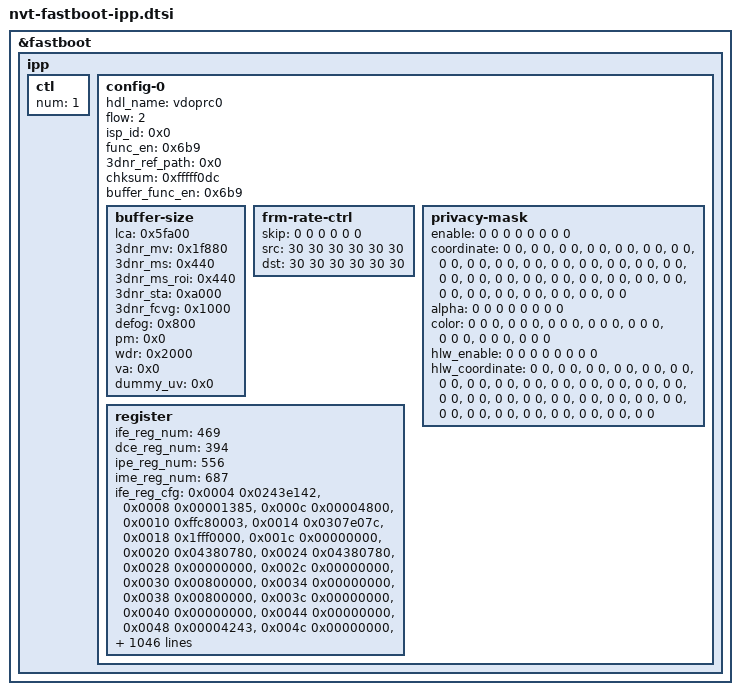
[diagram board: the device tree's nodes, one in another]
&fastboot {
	ipp {
		ctl {
			num = <1>;
		};
		config-0 {
			hdl_name = "vdoprc0";
			flow = <2>;
			isp_id = <0x0>;
			func_en = <0x6b9>;
			3dnr_ref_path = <0x0>;
			chksum = <0xfffff0dc>;
			buffer_func_en = <0x6b9>;
			buffer-size {
				lca = <0x5fa00>;
				3dnr_mv = <0x1f880>;
				3dnr_ms = <0x440>;
				3dnr_ms_roi = <0x440>;
				3dnr_sta = <0xa000>;
				3dnr_fcvg = <0x1000>;
				defog = <0x800>;
				pm = <0x0>;
				wdr = <0x2000>;
				va = <0x0>;
				dummy_uv = <0x0>;
			};
			frm-rate-ctrl {
				skip = <0 0 0 0 0 0>;
				src = <30 30 30 30 30 30>;
				dst = <30 30 30 30 30 30>;
			};
			privacy-mask {
				enable = <0 0 0 0 0 0 0 0>;
				coordinate =
					<0 0>, <0 0>, <0 0>, <0 0>,
					<0 0>, <0 0>, <0 0>, <0 0>,
					<0 0>, <0 0>, <0 0>, <0 0>,
					<0 0>, <0 0>, <0 0>, <0 0>,
					<0 0>, <0 0>, <0 0>, <0 0>,
					<0 0>, <0 0>, <0 0>, <0 0>,
					<0 0>, <0 0>, <0 0>, <0 0>,
					<0 0>, <0 0>, <0 0>, <0 0>;
				alpha = <0 0 0 0 0 0 0 0>;
				color =
					<0 0 0>,
					<0 0 0>,
					<0 0 0>,
					<0 0 0>,
					<0 0 0>,
					<0 0 0>,
					<0 0 0>,
					<0 0 0>;
				hlw_enable = <0 0 0 0 0 0 0 0>;
				hlw_coordinate =
					<0 0>, <0 0>, <0 0>, <0 0>,
					<0 0>, <0 0>, <0 0>, <0 0>,
					<0 0>, <0 0>, <0 0>, <0 0>,
					<0 0>, <0 0>, <0 0>, <0 0>,
					<0 0>, <0 0>, <0 0>, <0 0>,
					<0 0>, <0 0>, <0 0>, <0 0>,
					<0 0>, <0 0>, <0 0>, <0 0>,
					<0 0>, <0 0>, <0 0>, <0 0>;
			};
			register {
			  ife_reg_num = <469>;
			  dce_reg_num = <394>;
			  ipe_reg_num = <556>;
			  ime_reg_num = <687>;

			  ife_reg_cfg = 
			    <0x0004 0x0243e142>,
			    <0x0008 0x00001385>,
			    <0x000c 0x00004800>,
			    <0x0010 0xffc80003>,
			    <0x0014 0x0307e07c>,
			    <0x0018 0x1fff0000>,
			    <0x001c 0x00000000>,
			    <0x0020 0x04380780>,
			    <0x0024 0x04380780>,
			    <0x0028 0x00000000>,
			    <0x002c 0x00000000>,
			    <0x0030 0x00800000>,
			    <0x0034 0x00000000>,
			    <0x0038 0x00800000>,
			    <0x003c 0x00000000>,
			    <0x0040 0x00000000>,
			    <0x0044 0x00000000>,
			    <0x0048 0x00004243>,
			    <0x004c 0x00000000>,
			    <0x0050 0x00000000>,
			    <0x0054 0x00800000>,
			    <0x0058 0x00000000>,
			    <0x005c 0x00000000>,
			    <0x0060 0x00000000>,
			    <0x0064 0x00000000>,
			    <0x0068 0x000007a2>,
			    <0x006c 0x0001b987>,
			    <0x0070 0x000fff08>,
			    <0x0074 0x01120178>,
			    <0x0078 0x02670112>,
			    <0x007c 0x00000112>,
			    <0x0080 0x00800080>,
			    <0x0084 0x00800080>,
			    <0x0088 0x00000080>,
			    <0x008c 0x00800080>,
			    <0x0090 0x00800080>,
			    <0x0094 0x00000080>,
			    <0x0098 0x00000000>,
			    <0x009c 0x00000000>,
			    <0x00a0 0x00000000>,
			    <0x00a4 0x00000000>,
			    <0x00a8 0x00000000>,
			    <0x00ac 0x00000000>,
			    <0x00b0 0x01000100>,
			    <0x00b4 0x01000100>,
			    <0x00b8 0x00000100>,
			    <0x00bc 0x00000000>,
			    <0x00c0 0x00000000>,
			    <0x00c4 0x00000000>,
			    <0x00c8 0x00000000>,
			    <0x00cc 0x00000000>,
			    <0x00d0 0x00000000>,
			    <0x00d4 0x00000000>,
			    <0x00d8 0x00000000>,
			    <0x00dc 0x00000000>,
			    <0x00e0 0x00000000>,
			    <0x00e4 0x00000000>,
			    <0x00e8 0x00000000>,
			    <0x00ec 0x00000000>,
			    <0x00f0 0x00000000>,
			    <0x00f4 0x00000000>,
			    <0x00f8 0x00000000>,
			    <0x00fc 0x00000000>,
			    <0x0100 0x00080040>,
			    <0x0104 0x00000000>,
			    <0x0108 0x0911171f>,
			    <0x010c 0x00000307>,
			    <0x0110 0x00020000>,
			    <0x0114 0x00040003>,
			    <0x0118 0x00060005>,
			    <0x011c 0x00000000>,
			    <0x0120 0x00020000>,
			    <0x0124 0x00040003>,
			    <0x0128 0x00060005>,
			    <0x012c 0x00000000>,
			    <0x0130 0x00020000>,
			    <0x0134 0x00040003>,
			    <0x0138 0x00060005>,
			    <0x013c 0x00000000>,
			    <0x0140 0x00020000>,
			    <0x0144 0x00040003>,
			    <0x0148 0x00060005>,
			    <0x014c 0x00000000>,
			    <0x0150 0x00060000>,
			    <0x0154 0x000b0008>,
			    <0x0158 0x0013000e>,
			    <0x015c 0x00000000>,
			    <0x0160 0x00060000>,
			    <0x0164 0x000b0008>,
			    <0x0168 0x0013000e>,
			    <0x016c 0x00000000>,
			    <0x0170 0x00060000>,
			    <0x0174 0x000b0008>,
			    <0x0178 0x0013000e>,
			    <0x017c 0x00000000>,
			    <0x0180 0x00060000>,
			    <0x0184 0x000b0008>,
			    <0x0188 0x0013000e>,
			    <0x018c 0x00000000>,
			    <0x0190 0x002c62c6>,
			    <0x0194 0x0040c40c>,
			    <0x0198 0x006af6af>,
			    <0x019c 0x0093d93d>,
			    <0x01a0 0x00f41f41>,
			    <0x01a4 0x00010000>,
			    <0x01a8 0x00010033>,
			    <0x01ac 0x86543210>,
			    <0x01b0 0x86543210>,
			    <0x01b4 0x00f00001>,
			    <0x01b8 0x008000a0>,
			    <0x01bc 0x000010ff>,
			    <0x01c0 0x00030000>,
			    <0x01c4 0x00040003>,
			    <0x01c8 0x00060005>,
			    <0x01cc 0x00070006>,
			    <0x01d0 0x00080007>,
			    <0x01d4 0x00080008>,
			    <0x01d8 0x00090009>,
			    <0x01dc 0x000a0009>,
			    <0x01e0 0x0000000a>,
			    <0x01e4 0x00030000>,
			    <0x01e8 0x00040003>,
			    <0x01ec 0x00060005>,
			    <0x01f0 0x00070006>,
			    <0x01f4 0x00080007>,
			    <0x01f8 0x00080008>,
			    <0x01fc 0x00090009>,
			    <0x0200 0x000a0009>,
			    <0x0204 0x0000000a>,
			    <0x0208 0x00030000>,
			    <0x020c 0x00040003>,
			    <0x0210 0x00060005>,
			    <0x0214 0x00070006>,
			    <0x0218 0x00080007>,
			    <0x021c 0x00080008>,
			    <0x0220 0x00090009>,
			    <0x0224 0x000a0009>,
			    <0x0228 0x0000000a>,
			    <0x022c 0x00030000>,
			    <0x0230 0x00040003>,
			    <0x0234 0x00060005>,
			    <0x0238 0x00070006>,
			    <0x023c 0x00080007>,
			    <0x0240 0x00080008>,
			    <0x0244 0x00090009>,
			    <0x0248 0x000a0009>,
			    <0x024c 0x0000000a>,
			    <0x0250 0x00030000>,
			    <0x0254 0x00040003>,
			    <0x0258 0x00060005>,
			    <0x025c 0x00070006>,
			    <0x0260 0x00080007>,
			    <0x0264 0x00080008>,
			    <0x0268 0x00090009>,
			    <0x026c 0x000a0009>,
			    <0x0270 0x0000000a>,
			    <0x0274 0x00030000>,
			    <0x0278 0x00040003>,
			    <0x027c 0x00060005>,
			    <0x0280 0x00070006>,
			    <0x0284 0x00080007>,
			    <0x0288 0x00080008>,
			    <0x028c 0x00090009>,
			    <0x0290 0x000a0009>,
			    <0x0294 0x0000000a>,
			    <0x0298 0x00030000>,
			    <0x029c 0x00040003>,
			    <0x02a0 0x00060005>,
			    <0x02a4 0x00070006>,
			    <0x02a8 0x00080007>,
			    <0x02ac 0x00080008>,
			    <0x02b0 0x00090009>,
			    <0x02b4 0x000a0009>,
			    <0x02b8 0x0000000a>,
			    <0x02bc 0x00030000>,
			    <0x02c0 0x00040003>,
			    <0x02c4 0x00060005>,
			    <0x02c8 0x00070006>,
			    <0x02cc 0x00080007>,
			    <0x02d0 0x00080008>,
			    <0x02d4 0x00090009>,
			    <0x02d8 0x000a0009>,
			    <0x02dc 0x0000000a>,
			    <0x02e0 0x021c03c0>,
			    <0x02e4 0x021c03c0>,
			    <0x02e8 0x021c03c0>,
			    <0x02ec 0x021c03c0>,
			    <0x02f0 0x003b73b8>,
			    <0x02f4 0xfffc0001>,
			    <0x02f8 0x00000000>,
			    <0x02fc 0x00000000>,
			    <0x0300 0x00000000>,
			    <0x0304 0x00000000>,
			    <0x0308 0x00000000>,
			    <0x030c 0x00000000>,
			    <0x0310 0x00000000>,
			    <0x0314 0x00000000>,
			    <0x0318 0x00000000>,
			    <0x031c 0x00000000>,
			    <0x0320 0x00000000>,
			    <0x0324 0x00000000>,
			    <0x0328 0x00000000>,
			    <0x032c 0x00000000>,
			    <0x0330 0x00000000>,
			    <0x0334 0x00000000>,
			    <0x0338 0x00000000>,
			    <0x033c 0x00000000>,
			    <0x0340 0x00000000>,
			    <0x0344 0x00000000>,
			    <0x0348 0x00000000>,
			    <0x034c 0x00000000>,
			    <0x0350 0x00000000>,
			    <0x0354 0x00000000>,
			    <0x0358 0x00000000>,
			    <0x035c 0x00000000>,
			    <0x0360 0x00000000>,
			    <0x0364 0x00000000>,
			    <0x0368 0x00000000>,
			    <0x036c 0x00000000>,
			    <0x0370 0x00000000>,
			    <0x0374 0x00000000>,
			    <0x0378 0x00000000>,
			    <0x037c 0x00000000>,
			    <0x0380 0x00000000>,
			    <0x0384 0x00000000>,
			    <0x0388 0x09060301>,
			    <0x038c 0x15120f0d>,
			    <0x0390 0x211e1b18>,
			    <0x0394 0x2d2a2724>,
			    <0x0398 0x00000030>,
			    <0x039c 0x1b181000>,
			    <0x03a0 0x1f1e1c1b>,
			    <0x03a4 0x1c1d1e1f>,
			    <0x03a8 0x0c1a1b1c>,
			    <0x03ac 0x00000004>,
			    <0x03b0 0x00000000>,
			    <0x03b4 0x00000000>,
			    <0x03b8 0x00000000>,
			    <0x03bc 0x00000000>,
			    <0x03c0 0x1f1f1f1f>,
			    <0x03c4 0x1e1e1f1f>,
			    <0x03c8 0x14181c1d>,
			    <0x03cc 0x080a0c10>,
			    <0x03d0 0x06060606>,
			    <0x03d4 0x05050505>,
			    <0x03d8 0x04040404>,
			    <0x03dc 0x20010203>,
			    <0x03e0 0x00000000>,
			    <0x03e4 0x00000000>,
			    <0x03e8 0x00000000>,
			    <0x03ec 0x00000000>,
			    <0x03f0 0x00000000>,
			    <0x03f4 0x00000000>,
			    <0x03f8 0x00000000>,
			    <0x03fc 0x00000000>,
			    <0x0400 0x80000000>,
			    <0x0404 0x00000000>,
			    <0x0408 0x00000000>,
			    <0x040c 0x01000000>,
			    <0x0410 0x00000000>,
			    <0x0414 0x00000000>,
			    <0x0418 0x00000000>,
			    <0x041c 0x01000000>,
			    <0x0420 0x00000000>,
			    <0x0424 0x00000000>,
			    <0x0428 0x00000000>,
			    <0x042c 0x00000000>,
			    <0x0430 0x00000000>,
			    <0x0434 0x00000000>,
			    <0x0438 0x00000000>,
			    <0x043c 0x00000000>,
			    <0x0440 0x00000000>,
			    <0x0444 0x00000000>,
			    <0x0448 0x00000000>,
			    <0x044c 0x00000000>,
			    <0x0450 0x00000000>,
			    <0x0454 0x00000000>,
			    <0x0458 0x00000000>,
			    <0x045c 0x00000000>,
			    <0x0460 0x00000000>,
			    <0x0464 0x00000000>,
			    <0x0468 0x00000000>,
			    <0x046c 0x00000000>,
			    <0x0470 0x00000000>,
			    <0x0474 0x00000000>,
			    <0x0478 0x00000000>,
			    <0x047c 0x00000000>,
			    <0x0480 0x00000000>,
			    <0x0484 0x00000000>,
			    <0x0488 0x00000000>,
			    <0x048c 0x00000000>,
			    <0x0490 0x00000000>,
			    <0x0494 0x00000000>,
			    <0x0498 0x00000000>,
			    <0x049c 0x00000000>,
			    <0x04a0 0x00000000>,
			    <0x04a4 0x00000000>,
			    <0x04a8 0x00000000>,
			    <0x04ac 0x00000000>,
			    <0x04b0 0x00000000>,
			    <0x04b4 0x00000000>,
			    <0x04b8 0x00000000>,
			    <0x04bc 0x00000000>,
			    <0x04c0 0x00000000>,
			    <0x04c4 0x00000000>,
			    <0x04c8 0x00000000>,
			    <0x04cc 0x00000000>,
			    <0x04d0 0x00000000>,
			    <0x04d4 0x00000000>,
			    <0x04d8 0x00000000>,
			    <0x04dc 0x00000000>,
			    <0x04e0 0x00000000>,
			    <0x04e4 0x00000000>,
			    <0x04e8 0x00000000>,
			    <0x04ec 0x00000000>,
			    <0x04f0 0x00000000>,
			    <0x04f4 0x00000000>,
			    <0x04f8 0x00000000>,
			    <0x04fc 0x00000000>,
			    <0x0500 0x00000000>,
			    <0x0504 0x00000000>,
			    <0x0508 0x00000000>,
			    <0x050c 0x00000000>,
			    <0x0510 0x00000000>,
			    <0x0514 0x00000000>,
			    <0x0518 0x00000000>,
			    <0x051c 0x00000000>,
			    <0x0520 0x00000000>,
			    <0x0524 0x00000000>,
			    <0x0528 0x00000000>,
			    <0x052c 0x00000000>,
			    <0x0530 0x00000000>,
			    <0x0534 0x00000000>,
			    <0x0538 0x00000000>,
			    <0x053c 0x00000000>,
			    <0x0540 0x00000000>,
			    <0x0544 0x00000000>,
			    <0x0548 0x00000000>,
			    <0x054c 0x00000000>,
			    <0x0550 0x00100210>,
			    <0x0554 0x0e009c00>,
			    <0x0558 0x810060c0>,
			    <0x055c 0x0e009c00>,
			    <0x0560 0x810060c0>,
			    <0x0564 0x00000000>,
			    <0x0568 0x00000000>,
			    <0x056c 0x00000000>,
			    <0x0570 0x00000100>,
			    <0x0574 0x18a41040>,
			    <0x0578 0x10a63a0e>,
			    <0x057c 0x00000886>,
			    <0x0580 0x18a41040>,
			    <0x0584 0x10a63a0e>,
			    <0x0588 0x00000886>,
			    <0x058c 0x00000000>,
			    <0x0590 0xff100fff>,
			    <0x0594 0xff100fff>,
			    <0x0598 0x00000000>,
			    <0x059c 0x00000000>,
			    <0x05a0 0x00000000>,
			    <0x05a4 0x00000000>,
			    <0x05a8 0x00000000>,
			    <0x05ac 0x00000000>,
			    <0x05b0 0x00002222>,
			    <0x05b4 0x00000000>,
			    <0x05b8 0x00000000>,
			    <0x05bc 0x00000000>,
			    <0x05c0 0x00000000>,
			    <0x05c4 0x00000000>,
			    <0x05c8 0x00000000>,
			    <0x05cc 0x00000000>,
			    <0x05d0 0x00000000>,
			    <0x05d4 0x00000000>,
			    <0x05d8 0x00000000>,
			    <0x05dc 0x00000000>,
			    <0x05e0 0x00000000>,
			    <0x05e4 0x00000000>,
			    <0x05e8 0x00000000>,
			    <0x05ec 0x00000000>,
			    <0x05f0 0x00000000>,
			    <0x05f4 0x00000000>,
			    <0x05f8 0x00000000>,
			    <0x05fc 0x00000000>,
			    <0x0600 0x00000000>,
			    <0x0604 0x00000000>,
			    <0x0608 0x00000000>,
			    <0x060c 0x00000000>,
			    <0x0610 0x00000000>,
			    <0x0614 0x00000000>,
			    <0x0618 0x00000000>,
			    <0x061c 0x00000000>,
			    <0x0620 0x00000000>,
			    <0x0624 0x00000000>,
			    <0x0628 0x00000000>,
			    <0x062c 0x00000000>,
			    <0x0630 0x00000000>,
			    <0x0634 0x00000000>,
			    <0x0638 0x00000000>,
			    <0x063c 0x00000000>,
			    <0x0640 0x00000000>,
			    <0x0644 0x00000000>,
			    <0x0648 0x00000000>,
			    <0x064c 0x00000000>,
			    <0x0650 0x00000000>,
			    <0x0654 0x00000000>,
			    <0x0658 0x00000000>,
			    <0x065c 0x00000000>,
			    <0x0660 0x00000000>,
			    <0x0664 0x00000000>,
			    <0x0668 0x00000000>,
			    <0x066c 0x00000000>,
			    <0x0670 0x00000000>,
			    <0x0674 0x00000000>,
			    <0x0678 0x00000000>,
			    <0x067c 0x00000000>,
			    <0x0680 0x00000000>,
			    <0x0684 0x00000000>,
			    <0x0688 0x00000000>,
			    <0x068c 0x00000000>,
			    <0x0690 0x00000000>,
			    <0x0694 0x00000000>,
			    <0x0698 0x00000000>,
			    <0x069c 0x00000000>,
			    <0x06a0 0x00000000>,
			    <0x06a4 0x00000000>,
			    <0x06a8 0x00000000>,
			    <0x06ac 0x00000000>,
			    <0x06b0 0x00000000>,
			    <0x06b4 0x00000000>,
			    <0x06b8 0x00000000>,
			    <0x06bc 0x00000000>,
			    <0x06c0 0x00000000>,
			    <0x06c4 0x00000000>,
			    <0x06c8 0x00000000>,
			    <0x06cc 0x00000000>,
			    <0x06d0 0x00000000>,
			    <0x06d4 0x00000000>,
			    <0x06d8 0x00000000>,
			    <0x06dc 0x00000000>,
			    <0x06e0 0x00000000>,
			    <0x06e4 0x00000000>,
			    <0x06e8 0x00000000>,
			    <0x06ec 0x00000000>,
			    <0x06f0 0x00000000>,
			    <0x06f4 0x00000000>,
			    <0x06f8 0x00000000>,
			    <0x06fc 0x00000000>,
			    <0x0700 0x00000000>,
			    <0x0704 0x00000000>,
			    <0x0708 0x00000000>,
			    <0x070c 0x00000000>,
			    <0x0710 0x0002aaaa>,
			    <0x0714 0x00000000>,
			    <0x0718 0x00000000>,
			    <0x071c 0x00000000>,
			    <0x0720 0x00000000>,
			    <0x0724 0x00000000>,
			    <0x0728 0x00000000>,
			    <0x072c 0x00000000>,
			    <0x0730 0x00000000>,
			    <0x0734 0x00000000>,
			    <0x0738 0x00000000>,
			    <0x073c 0x00000000>,
			    <0x0740 0x00000000>,
			    <0x0744 0x00000000>,
			    <0x0748 0x00000000>,
			    <0x074c 0x00000000>,
			    <0x0750 0x00000000>,
			    <0x0754 0x00000000>;

			  dce_reg_cfg = 
			    <0x0004 0x0000467a>,
			    <0x0008 0x0000101b>,
			    <0x000c 0x00000000>,
			    <0x0010 0x04380780>,
			    <0x0014 0x00000000>,
			    <0x0018 0x00000010>,
			    <0x001c 0x00400000>,
			    <0x0020 0x00400000>,
			    <0x0024 0x00000780>,
			    <0x0028 0x00400000>,
			    <0x002c 0x00000780>,
			    <0x0030 0x00400000>,
			    <0x0034 0x00000780>,
			    <0x0038 0x00400000>,
			    <0x003c 0x00000780>,
			    <0x0040 0x00000011>,
			    <0x0044 0x1e0781e0>,
			    <0x0048 0x1e0781e0>,
			    <0x004c 0x1e0781e0>,
			    <0x0050 0x1e0781e0>,
			    <0x0054 0x1e0781e0>,
			    <0x0058 0x000001e0>,
			    <0x005c 0x7f000000>,
			    <0x0060 0x00003003>,
			    <0x0064 0x077f0000>,
			    <0x0068 0x077f0000>,
			    <0x006c 0x0000001e>,
			    <0x0070 0x00000000>,
			    <0x0074 0x00000000>,
			    <0x0078 0x00000000>,
			    <0x007c 0x00000000>,
			    <0x0080 0x00000000>,
			    <0x0084 0x00000000>,
			    <0x0088 0x00000000>,
			    <0x008c 0x00000780>,
			    <0x0090 0x00000000>,
			    <0x0094 0x00000000>,
			    <0x0098 0x00000000>,
			    <0x009c 0x00000000>,
			    <0x00a0 0x00000000>,
			    <0x00a4 0x00400000>,
			    <0x00a8 0x2c0003c0>,
			    <0x00ac 0x000a0028>,
			    <0x00b0 0x80000000>,
			    <0x00b4 0x00000000>,
			    <0x00b8 0xf8888888>,
			    <0x00bc 0x485f7880>,
			    <0x00c0 0x2428303a>,
			    <0x00c4 0x20202020>,
			    <0x00c8 0x20202020>,
			    <0x00cc 0x00a00020>,
			    <0x00d0 0x00014008>,
			    <0x00d4 0x122347ff>,
			    <0x00d8 0x00000111>,
			    <0x00dc 0x00000000>,
			    <0x00e0 0x40081007>,
			    <0x00e4 0x00408003>,
			    <0x00e8 0x00cc00cc>,
			    <0x00ec 0xa80080e6>,
			    <0x00f0 0x00800080>,
			    <0x00f4 0x00010080>,
			    <0x00f8 0x00000100>,
			    <0x00fc 0xffffe0c0>,
			    <0x0100 0x00000000>,
			    <0x0104 0x00000000>,
			    <0x0108 0x00000000>,
			    <0x010c 0x00000000>,
			    <0x0110 0x00000000>,
			    <0x0114 0x00000000>,
			    <0x0118 0x00000000>,
			    <0x011c 0x00000000>,
			    <0x0120 0x0000023f>,
			    <0x0124 0x02c53f40>,
			    <0x0128 0x00000100>,
			    <0x012c 0x02c51f40>,
			    <0x0130 0x00000100>,
			    <0x0134 0x04080422>,
			    <0x0138 0x0f79cc3b>,
			    <0x013c 0x0fde1c3b>,
			    <0x0140 0x00000000>,
			    <0x0144 0x00000000>,
			    <0x0148 0x00000000>,
			    <0x014c 0x00000000>,
			    <0x0150 0x00000000>,
			    <0x0154 0x20000000>,
			    <0x0158 0x00000054>,
			    <0x015c 0x1565193c>,
			    <0x0160 0x160c160c>,
			    <0x0164 0x55050003>,
			    <0x0168 0x00000000>,
			    <0x016c 0x00000000>,
			    <0x0170 0x00000000>,
			    <0x0174 0x00000000>,
			    <0x0178 0x00000000>,
			    <0x017c 0x00000000>,
			    <0x0180 0x00000000>,
			    <0x0184 0x00000000>,
			    <0x0188 0x00000000>,
			    <0x018c 0x00000000>,
			    <0x0190 0x00000000>,
			    <0x0194 0x00000000>,
			    <0x0198 0x00000000>,
			    <0x019c 0x00000000>,
			    <0x01a0 0x00000000>,
			    <0x01a4 0x00000000>,
			    <0x01a8 0x00000000>,
			    <0x01ac 0x00000000>,
			    <0x01b0 0x00000000>,
			    <0x01b4 0x00000000>,
			    <0x01b8 0x00000000>,
			    <0x01bc 0x00000000>,
			    <0x01c0 0x00000000>,
			    <0x01c4 0x00000000>,
			    <0x01c8 0x00000000>,
			    <0x01cc 0x00000000>,
			    <0x01d0 0x00000000>,
			    <0x01d4 0x00000000>,
			    <0x01d8 0x00000000>,
			    <0x01dc 0x00000000>,
			    <0x01e0 0x00000000>,
			    <0x01e4 0x00000000>,
			    <0x01e8 0x00000000>,
			    <0x01ec 0x00000000>,
			    <0x01f0 0x00000000>,
			    <0x01f4 0x00000000>,
			    <0x01f8 0x00000000>,
			    <0x01fc 0x00000000>,
			    <0x0200 0x00000000>,
			    <0x0204 0x00000000>,
			    <0x0208 0x00000000>,
			    <0x020c 0x00000000>,
			    <0x0210 0x00000000>,
			    <0x0214 0x18100800>,
			    <0x0218 0x2624201c>,
			    <0x021c 0x2b2a2928>,
			    <0x0220 0x2f2e2d2c>,
			    <0x0224 0x33323130>,
			    <0x0228 0x37363534>,
			    <0x022c 0x3b3a3938>,
			    <0x0230 0x3f3e3d3c>,
			    <0x0234 0x00005abf>,
			    <0x0238 0x00000000>,
			    <0x023c 0x0ff70fff>,
			    <0x0240 0x0fa10fd8>,
			    <0x0244 0x0ef10f54>,
			    <0x0248 0x0df70e7b>,
			    <0x024c 0x0cd10d68>,
			    <0x0250 0x0b9d0c37>,
			    <0x0254 0x0a700b04>,
			    <0x0258 0x095909e1>,
			    <0x025c 0x085f08d8>,
			    <0x0260 0x078407ee>,
			    <0x0264 0x06c70722>,
			    <0x0268 0x06240673>,
			    <0x026c 0x055c05dc>,
			    <0x0270 0x049004ee>,
			    <0x0274 0x03f9043f>,
			    <0x0278 0x038803bd>,
			    <0x027c 0x0332035b>,
			    <0x0280 0x02f0030f>,
			    <0x0284 0x02a602d4>,
			    <0x0288 0x02620280>,
			    <0x028c 0x02230249>,
			    <0x0290 0x01f30208>,
			    <0x0294 0x01d801e4>,
			    <0x0298 0x01c801cf>,
			    <0x029c 0x01bd01c2>,
			    <0x02a0 0x01b501b9>,
			    <0x02a4 0x01b001b2>,
			    <0x02a8 0x01ac01ae>,
			    <0x02ac 0x01a901aa>,
			    <0x02b0 0x01a601a7>,
			    <0x02b4 0x01a401a5>,
			    <0x02b8 0x01a301a4>,
			    <0x02bc 0x000001a2>,
			    <0x02c0 0x00008040>,
			    <0x02c4 0xffff0000>,
			    <0x02c8 0x00000000>,
			    <0x02cc 0x00000000>,
			    <0x02d0 0x00000000>,
			    <0x02d4 0x00000000>,
			    <0x02d8 0x020a0000>,
			    <0x02dc 0x2bba0c3b>,
			    <0x02e0 0xb8c3749e>,
			    <0x02e4 0xffffffff>,
			    <0x02e8 0xffffffff>,
			    <0x02ec 0xffffffff>,
			    <0x02f0 0xe1c1ffff>,
			    <0x02f4 0xcf72e582>,
			    <0x02f8 0x9468acbd>,
			    <0x02fc 0x74608664>,
			    <0x0300 0x68946fc0>,
			    <0x0304 0x4b605fce>,
			    <0x0308 0x2f573b99>,
			    <0x030c 0x29122d1b>,
			    <0x0310 0x2363257f>,
			    <0x0314 0x21ab2390>,
			    <0x0318 0x1d8d1f29>,
			    <0x031c 0x20091db5>,
			    <0x0320 0x24f425d0>,
			    <0x0324 0x228c23ca>,
			    <0x0328 0x2816233c>,
			    <0x032c 0x33bc2f0b>,
			    <0x0330 0x30b130b5>,
			    <0x0334 0x30b1300c>,
			    <0x0338 0x2f5b2fc0>,
			    <0x033c 0x2bc22e56>,
			    <0x0340 0x28e72a17>,
			    <0x0344 0x2c2a2605>,
			    <0x0348 0x2a9e2f6e>,
			    <0x034c 0x264525ac>,
			    <0x0350 0x275a26fd>,
			    <0x0354 0x28af28b7>,
			    <0x0358 0x25a526eb>,
			    <0x035c 0x20f32345>,
			    <0x0360 0x1b891de8>,
			    <0x0364 0x1b961af1>,
			    <0x0368 0x1cf11bb3>,
			    <0x036c 0x26c71f83>,
			    <0x0370 0x34f83350>,
			    <0x0374 0x2b432dc9>,
			    <0x0378 0x29cd2881>,
			    <0x037c 0x2aed2c94>,
			    <0x0380 0x2c902c79>,
			    <0x0384 0x22a2290d>,
			    <0x0388 0x17d31a7a>,
			    <0x038c 0x130a16ec>,
			    <0x0390 0x0e631047>,
			    <0x0394 0x0d580db3>,
			    <0x0398 0x0d180d60>,
			    <0x039c 0x0b690c2f>,
			    <0x03a0 0x0c650be4>,
			    <0x03a4 0x0bb70b4c>,
			    <0x03a8 0x0ac80b07>,
			    <0x03ac 0x0acb0ab9>,
			    <0x03b0 0x0a920add>,
			    <0x03b4 0x0a000aad>,
			    <0x03b8 0x0b860a9f>,
			    <0x03bc 0x0c190bc9>,
			    <0x03c0 0x0d500cfb>,
			    <0x03c4 0x0f1b0e2f>,
			    <0x03c8 0x135410cc>,
			    <0x03cc 0x1afe1743>,
			    <0x03d0 0xffff2093>,
			    <0x03d4 0x00000000>,
			    <0x03d8 0x00000000>,
			    <0x03dc 0x00000000>,
			    <0x03e0 0x00000000>,
			    <0x03e4 0x00000000>,
			    <0x03e8 0x00000000>,
			    <0x03ec 0x00000000>,
			    <0x03f0 0x00000000>,
			    <0x03f4 0x00000000>,
			    <0x03f8 0x00000000>,
			    <0x03fc 0x00000000>,
			    <0x0400 0x00000000>,
			    <0x0404 0x021c03c0>,
			    <0x0408 0x00ffffff>,
			    <0x040c 0x032916ca>,
			    <0x0410 0x00000400>,
			    <0x0414 0x3fffffff>,
			    <0x0418 0x10001000>,
			    <0x041c 0x00001000>,
			    <0x0420 0x00000000>,
			    <0x0424 0x00000000>,
			    <0x0428 0x00000000>,
			    <0x042c 0x00000000>,
			    <0x0430 0x00000000>,
			    <0x0434 0x00000000>,
			    <0x0438 0x00000000>,
			    <0x043c 0x00000000>,
			    <0x0440 0xffffffff>,
			    <0x0444 0xffffffff>,
			    <0x0448 0xffffffff>,
			    <0x044c 0xffffffff>,
			    <0x0450 0xffffffff>,
			    <0x0454 0xffffffff>,
			    <0x0458 0xffffffff>,
			    <0x045c 0xffffffff>,
			    <0x0460 0xffffffff>,
			    <0x0464 0xffffffff>,
			    <0x0468 0xffffffff>,
			    <0x046c 0xffffffff>,
			    <0x0470 0xffffffff>,
			    <0x0474 0xffffffff>,
			    <0x0478 0xffffffff>,
			    <0x047c 0xffffffff>,
			    <0x0480 0xffffffff>,
			    <0x0484 0xffffffff>,
			    <0x0488 0xffffffff>,
			    <0x048c 0xffffffff>,
			    <0x0490 0xffffffff>,
			    <0x0494 0xffffffff>,
			    <0x0498 0xffffffff>,
			    <0x049c 0xffffffff>,
			    <0x04a0 0xffffffff>,
			    <0x04a4 0xffffffff>,
			    <0x04a8 0xffffffff>,
			    <0x04ac 0xffffffff>,
			    <0x04b0 0xffffffff>,
			    <0x04b4 0xffffffff>,
			    <0x04b8 0xffffffff>,
			    <0x04bc 0xffffffff>,
			    <0x04c0 0x0000ffff>,
			    <0x04c4 0x00000000>,
			    <0x04c8 0x00000000>,
			    <0x04cc 0x00000000>,
			    <0x04d0 0x00000000>,
			    <0x04d4 0x00000000>,
			    <0x04d8 0x00000000>,
			    <0x04dc 0x00000000>,
			    <0x04e0 0x00000000>,
			    <0x04e4 0x00000000>,
			    <0x04e8 0x00000000>,
			    <0x04ec 0x00000000>,
			    <0x04f0 0x00000000>,
			    <0x04f4 0x00000000>,
			    <0x04f8 0x00000000>,
			    <0x04fc 0x00000000>,
			    <0x0500 0x00000000>,
			    <0x0504 0x00000000>,
			    <0x0508 0x00000000>,
			    <0x050c 0x00000000>,
			    <0x0510 0x00000000>,
			    <0x0514 0x00000000>,
			    <0x0518 0x00000000>,
			    <0x051c 0x00000000>,
			    <0x0520 0x00000000>,
			    <0x0524 0x00000000>,
			    <0x0528 0x00000000>,
			    <0x052c 0x00000000>,
			    <0x0530 0x00000000>,
			    <0x0534 0x00000000>,
			    <0x0538 0x00000000>,
			    <0x053c 0x00000000>,
			    <0x0540 0x00000000>,
			    <0x0544 0x00000000>,
			    <0x0548 0x00000000>,
			    <0x054c 0x00000000>,
			    <0x0550 0x00000000>,
			    <0x0554 0x00000000>,
			    <0x0558 0x00000000>,
			    <0x055c 0x00000000>,
			    <0x0560 0x00000000>,
			    <0x0564 0x00000000>,
			    <0x0568 0x00000000>,
			    <0x056c 0x00000000>,
			    <0x0570 0x00000000>,
			    <0x0574 0x00000000>,
			    <0x0578 0x00000000>,
			    <0x057c 0x00000000>,
			    <0x0580 0x00000000>,
			    <0x0584 0x00000000>,
			    <0x0588 0x00000000>,
			    <0x058c 0x00000000>,
			    <0x0590 0x00000000>,
			    <0x0594 0x00000000>,
			    <0x0598 0x00000000>,
			    <0x059c 0x00000000>,
			    <0x05a0 0x00000000>,
			    <0x05a4 0x00000000>,
			    <0x05a8 0x00000000>,
			    <0x05ac 0x00000000>,
			    <0x05b0 0x00000000>,
			    <0x05b4 0x00000000>,
			    <0x05b8 0x00000000>,
			    <0x05bc 0x00000000>,
			    <0x05c0 0x00000000>,
			    <0x05c4 0x00000000>,
			    <0x05c8 0x00000000>,
			    <0x05cc 0x00000000>,
			    <0x05d0 0x00000000>,
			    <0x05d4 0x00000000>,
			    <0x05d8 0x00000000>,
			    <0x05dc 0x00000000>,
			    <0x05e0 0x00000000>,
			    <0x05e4 0x00000000>,
			    <0x05e8 0x00000000>,
			    <0x05ec 0x00000000>,
			    <0x05f0 0x00400000>,
			    <0x05f4 0x00000000>,
			    <0x05f8 0x00000000>,
			    <0x05fc 0x00000000>,
			    <0x0600 0x00000000>,
			    <0x0604 0x00000000>,
			    <0x0608 0x00000000>,
			    <0x060c 0x00000000>,
			    <0x0610 0x20200930>,
			    <0x0614 0x00000000>,
			    <0x0618 0x00000000>,
			    <0x061c 0x00000000>,
			    <0x0620 0x00000000>,
			    <0x0624 0x00000000>,
			    <0x0628 0x80000000>;

			  ipe_reg_cfg = 
			    <0x0004 0x00000006>,
			    <0x0008 0x01f17eda>,
			    <0x000c 0x00000010>,
			    <0x0010 0x00000000>,
			    <0x0014 0x001e0000>,
			    <0x0018 0x00000438>,
			    <0x001c 0x00000000>,
			    <0x0020 0x00000000>,
			    <0x0024 0x00000000>,
			    <0x0028 0x00000000>,
			    <0x002c 0x02b6dcfc>,
			    <0x0030 0x00000000>,
			    <0x0034 0x00000000>,
			    <0x0038 0x00800000>,
			    <0x003c 0x00800000>,
			    <0x0040 0x00000000>,
			    <0x0044 0x00000000>,
			    <0x0048 0x10000000>,
			    <0x004c 0x00000000>,
			    <0x0050 0x0000100a>,
			    <0x0054 0x00000064>,
			    <0x0058 0xff040001>,
			    <0x005c 0x00000000>,
			    <0x0060 0x00000000>,
			    <0x0064 0x00000000>,
			    <0x0068 0x00000000>,
			    <0x006c 0x00000000>,
			    <0x0070 0x017c05a3>,
			    <0x0074 0x3e2ec02a>,
			    <0x0078 0x00a013dd>,
			    <0x007c 0x0010100a>,
			    <0x0080 0x00181818>,
			    <0x0084 0x00000333>,
			    <0x0088 0x00010004>,
			    <0x008c 0x00008868>,
			    <0x0090 0x88681000>,
			    <0x0094 0x00082028>,
			    <0x0098 0xffc8201f>,
			    <0x009c 0x00a500b6>,
			    <0x00a0 0x00800801>,
			    <0x00a4 0xffff3180>,
			    <0x00a8 0x00010000>,
			    <0x00ac 0x01000100>,
			    <0x00b0 0x00600060>,
			    <0x00b4 0x05080000>,
			    <0x00b8 0x40352d20>,
			    <0x00bc 0x40404040>,
			    <0x00c0 0x40404040>,
			    <0x00c4 0x262c3440>,
			    <0x00c8 0x14020000>,
			    <0x00cc 0x7a573000>,
			    <0x00d0 0xffddb79a>,
			    <0x00d4 0xaac0e0ff>,
			    <0x00d8 0x8088909a>,
			    <0x00dc 0x038dbbff>,
			    <0x00e0 0x40400001>,
			    <0x00e4 0x0400fc00>,
			    <0x00e8 0x00005020>,
			    <0x00ec 0x00000000>,
			    <0x00f0 0x00000000>,
			    <0x00f4 0x00000000>,
			    <0x00f8 0x00000000>,
			    <0x00fc 0x00000000>,
			    <0x0100 0x01a80001>,
			    <0x0104 0x0fd70f81>,
			    <0x0108 0x017c0f9d>,
			    <0x010c 0x00470fe8>,
			    <0x0110 0x01e70ed2>,
			    <0x0114 0x00104080>,
			    <0x0118 0x00000000>,
			    <0x011c 0x00000000>,
			    <0x0120 0x00000000>,
			    <0x0124 0x050a0f14>,
			    <0x0128 0x00000000>,
			    <0x012c 0x00000000>,
			    <0x0130 0x0f0a0500>,
			    <0x0134 0x00000000>,
			    <0x0138 0x80752c4d>,
			    <0x013c 0x120357d5>,
			    <0x0140 0x07af2a80>,
			    <0x0144 0x00000000>,
			    <0x0148 0x28200000>,
			    <0x014c 0x80808080>,
			    <0x0150 0x80808080>,
			    <0x0154 0x80808080>,
			    <0x0158 0x80808080>,
			    <0x015c 0x80808080>,
			    <0x0160 0x80808080>,
			    <0x0164 0x00000000>,
			    <0x0168 0x00000000>,
			    <0x016c 0x00000000>,
			    <0x0170 0x00000000>,
			    <0x0174 0x00000000>,
			    <0x0178 0x00000000>,
			    <0x017c 0x00000000>,
			    <0x0180 0x00000000>,
			    <0x0184 0x00000000>,
			    <0x0188 0x00000000>,
			    <0x018c 0x00000000>,
			    <0x0190 0x00000000>,
			    <0x0194 0x7b76767b>,
			    <0x0198 0x7676767b>,
			    <0x019c 0x807b7676>,
			    <0x01a0 0x80808080>,
			    <0x01a4 0x80808080>,
			    <0x01a8 0x80808080>,
			    <0x01ac 0x00820820>,
			    <0x01b0 0x00820820>,
			    <0x01b4 0x00000000>,
			    <0x01b8 0x0002308c>,
			    <0x01bc 0x00000080>,
			    <0x01c0 0x00000000>,
			    <0x01c4 0x00000000>,
			    <0x01c8 0x00ffffff>,
			    <0x01cc 0x00808080>,
			    <0x01d0 0x80808080>,
			    <0x01d4 0x00000000>,
			    <0x01d8 0x00000000>,
			    <0x01dc 0x08020080>,
			    <0x01e0 0x08020080>,
			    <0x01e4 0x08020080>,
			    <0x01e8 0x08020080>,
			    <0x01ec 0x08020080>,
			    <0x01f0 0x00020080>,
			    <0x01f4 0x00000000>,
			    <0x01f8 0x00000000>,
			    <0x01fc 0x00000000>,
			    <0x0200 0x00000000>,
			    <0x0204 0x00000000>,
			    <0x0208 0x00000000>,
			    <0x020c 0x00000000>,
			    <0x0210 0x00000000>,
			    <0x0214 0x00000000>,
			    <0x0218 0x00000000>,
			    <0x021c 0x210f0080>,
			    <0x0220 0x210f0080>,
			    <0x0224 0x310f0002>,
			    <0x0228 0x310f0002>,
			    <0x022c 0x00000000>,
			    <0x0230 0x00000000>,
			    <0x0234 0x00000000>,
			    <0x0238 0x00300000>,
			    <0x023c 0x00000000>,
			    <0x0240 0x01e40360>,
			    <0x0244 0x006c0c00>,
			    <0x0248 0x00d80180>,
			    <0x024c 0x006c0c00>,
			    <0x0250 0x00d80540>,
			    <0x0254 0x006c0c00>,
			    <0x0258 0x02f40180>,
			    <0x025c 0x006c0c00>,
			    <0x0260 0x02f40540>,
			    <0x0264 0x006c0c00>,
			    <0x0268 0x138b80e8>,
			    <0x026c 0x13899828>,
			    <0x0270 0x12fec8c6>,
			    <0x0274 0x12fbe066>,
			    <0x0278 0x12dea1c8>,
			    <0x027c 0x12c7df67>,
			    <0x0280 0x1208bde6>,
			    <0x0284 0x11d1a2a6>,
			    <0x0288 0x130aa486>,
			    <0x028c 0x12fda406>,
			    <0x0290 0x12909046>,
			    <0x0294 0x12838ce6>,
			    <0x0298 0x13b2ed48>,
			    <0x029c 0x13f0de49>,
			    <0x02a0 0x12c1f1e6>,
			    <0x02a4 0x1317b187>,
			    <0x02a8 0x13afdd07>,
			    <0x02ac 0x142ad569>,
			    <0x02b0 0x12848806>,
			    <0x02b4 0x13308087>,
			    <0x02b8 0x00000000>,
			    <0x02bc 0x00000000>,
			    <0x02c0 0x0000010f>,
			    <0x02c4 0x02c51740>,
			    <0x02c8 0x00000040>,
			    <0x02cc 0x02c50f40>,
			    <0x02d0 0x00000040>,
			    <0x02d4 0x01e50200>,
			    <0x02d8 0x1ffbb877>,
			    <0x02dc 0x21b80077>,
			    <0x02e0 0x00000000>,
			    <0x02e4 0x00000000>,
			    <0x02e8 0x00000000>,
			    <0x02ec 0x00000000>,
			    <0x02f0 0x00000054>,
			    <0x02f4 0x00000000>,
			    <0x02f8 0x00000000>,
			    <0x02fc 0x00000000>,
			    <0x0300 0x00000000>,
			    <0x0304 0x00000000>,
			    <0x0308 0x00000000>,
			    <0x030c 0x00000000>,
			    <0x0310 0x00000000>,
			    <0x0314 0x00000000>,
			    <0x0318 0x00000000>,
			    <0x031c 0x00000000>,
			    <0x0320 0x00000000>,
			    <0x0324 0x00000000>,
			    <0x0328 0x00000000>,
			    <0x032c 0x00000000>,
			    <0x0330 0x00000000>,
			    <0x0334 0x00000000>,
			    <0x0338 0x00000000>,
			    <0x033c 0x00000000>,
			    <0x0340 0x00000000>,
			    <0x0344 0x00000000>,
			    <0x0348 0x00000000>,
			    <0x034c 0x00000000>,
			    <0x0350 0x00000000>,
			    <0x0354 0x00000000>,
			    <0x0358 0x00000000>,
			    <0x035c 0x00000000>,
			    <0x0360 0x00000000>,
			    <0x0364 0x00000000>,
			    <0x0368 0x00000000>,
			    <0x036c 0x00000000>,
			    <0x0370 0x00000000>,
			    <0x0374 0x00000000>,
			    <0x0378 0x00000000>,
			    <0x037c 0x00000000>,
			    <0x0380 0x00000000>,
			    <0x0384 0x00800000>,
			    <0x0388 0x54545454>,
			    <0x038c 0x54545454>,
			    <0x0390 0x00000054>,
			    <0x0394 0x00000000>,
			    <0x0398 0x00000000>,
			    <0x039c 0x00000000>,
			    <0x03a0 0x00000000>,
			    <0x03a4 0x00000000>,
			    <0x03a8 0x00000000>,
			    <0x03ac 0x00000000>,
			    <0x03b0 0x00000000>,
			    <0x03b4 0x00000000>,
			    <0x03b8 0x00000000>,
			    <0x03bc 0x00000000>,
			    <0x03c0 0x00000000>,
			    <0x03c4 0x00000000>,
			    <0x03c8 0x00000000>,
			    <0x03cc 0x00000000>,
			    <0x03d0 0x00000000>,
			    <0x03d4 0x00000000>,
			    <0x03d8 0x00000000>,
			    <0x03dc 0x00000000>,
			    <0x03e0 0x00000000>,
			    <0x03e4 0x00000000>,
			    <0x03e8 0x00000000>,
			    <0x03ec 0x00000000>,
			    <0x03f0 0x00000000>,
			    <0x03f4 0x00000000>,
			    <0x03f8 0x00000000>,
			    <0x03fc 0x00000000>,
			    <0x0400 0x19b63d82>,
			    <0x0404 0x19b63d82>,
			    <0x0408 0x2e8b8edd>,
			    <0x040c 0x25f96652>,
			    <0x0410 0x1825d568>,
			    <0x0414 0x1825d568>,
			    <0x0418 0x1825d568>,
			    <0x041c 0x1825d568>,
			    <0x0420 0x1825d568>,
			    <0x0424 0x1825d569>,
			    <0x0428 0x1825d568>,
			    <0x042c 0x1825d568>,
			    <0x0430 0x1825d568>,
			    <0x0434 0x1825d568>,
			    <0x0438 0x1825d568>,
			    <0x043c 0x372db768>,
			    <0x0440 0x13048511>,
			    <0x0444 0x19b63d82>,
			    <0x0448 0x19b63d82>,
			    <0x044c 0x19b63d82>,
			    <0x0450 0x19b63d82>,
			    <0x0454 0x19b63d82>,
			    <0x0458 0x25f96652>,
			    <0x045c 0x16856d4d>,
			    <0x0460 0x1825d568>,
			    <0x0464 0x1825d568>,
			    <0x0468 0x1825d568>,
			    <0x046c 0x1825d568>,
			    <0x0470 0x1825d568>,
			    <0x0474 0x2ddb5ed1>,
			    <0x0478 0x25f96652>,
			    <0x047c 0x19b63d82>,
			    <0x0480 0x19b63d82>,
			    <0x0484 0x19b63d82>,
			    <0x0488 0x19b63d82>,
			    <0x048c 0x19b63d82>,
			    <0x0490 0x19b63d82>,
			    <0x0494 0x1825d568>,
			    <0x0498 0x1825d568>,
			    <0x049c 0x1825d568>,
			    <0x04a0 0x1825d568>,
			    <0x04a4 0x1825d568>,
			    <0x04a8 0x36ad935f>,
			    <0x04ac 0x13048511>,
			    <0x04b0 0x1825d568>,
			    <0x04b4 0x1825d568>,
			    <0x04b8 0x1825d568>,
			    <0x04bc 0x1825d568>,
			    <0x04c0 0x1825d568>,
			    <0x04c4 0x111404f1>,
			    <0x04c8 0x111404f1>,
			    <0x04cc 0x1825d568>,
			    <0x04d0 0x1825d568>,
			    <0x04d4 0x1825d568>,
			    <0x04d8 0x1825d568>,
			    <0x04dc 0x1825d568>,
			    <0x04e0 0x19b63d82>,
			    <0x04e4 0x19b63d82>,
			    <0x04e8 0x19b63d82>,
			    <0x04ec 0x19b63d82>,
			    <0x04f0 0x19b63d82>,
			    <0x04f4 0x19b63d82>,
			    <0x04f8 0x33acd730>,
			    <0x04fc 0x13448511>,
			    <0x0500 0x1b16999b>,
			    <0x0504 0x1b16999b>,
			    <0x0508 0x1b16999b>,
			    <0x050c 0x1b16999b>,
			    <0x0510 0x1b16999b>,
			    <0x0514 0x2368c229>,
			    <0x0518 0x16856d4d>,
			    <0x051c 0x1c76f1b1>,
			    <0x0520 0x1c76f1b1>,
			    <0x0524 0x1c76f1b1>,
			    <0x0528 0x1c76f1b1>,
			    <0x052c 0x1c76f1b1>,
			    <0x0530 0x2e8b8edd>,
			    <0x0534 0x26d99a5f>,
			    <0x0538 0x1c76f1b1>,
			    <0x053c 0x1c76f1b1>,
			    <0x0540 0x1c76f1b1>,
			    <0x0544 0x1c76f1b1>,
			    <0x0548 0x1c76f1b1>,
			    <0x054c 0x13048511>,
			    <0x0550 0x1c76f1b1>,
			    <0x0554 0x1c76f1b1>,
			    <0x0558 0x1c76f1b1>,
			    <0x055c 0x1c76f1b1>,
			    <0x0560 0x1c76f1b1>,
			    <0x0564 0x20f819fe>,
			    <0x0568 0x14d4f930>,
			    <0x056c 0x1c76f1b1>,
			    <0x0570 0x1c76f1b1>,
			    <0x0574 0x1c76f1b1>,
			    <0x0578 0x1c76f1b1>,
			    <0x057c 0x1c76f1b1>,
			    <0x0580 0x1b16999b>,
			    <0x0584 0x1b16999b>,
			    <0x0588 0x1b16999b>,
			    <0x058c 0x1b16999b>,
			    <0x0590 0x25292e44>,
			    <0x0594 0x1825d568>,
			    <0x0598 0x1b16999b>,
			    <0x059c 0x1b16999b>,
			    <0x05a0 0x1b16999b>,
			    <0x05a4 0x1b16999b>,
			    <0x05a8 0x1b16999b>,
			    <0x05ac 0x2f4bbae9>,
			    <0x05b0 0x293a3687>,
			    <0x05b4 0x1b16999b>,
			    <0x05b8 0x1b16999b>,
			    <0x05bc 0x1b16999b>,
			    <0x05c0 0x1b16999b>,
			    <0x05c4 0x1b16999b>,
			    <0x05c8 0x14d4f931>,
			    <0x05cc 0x1b16999b>,
			    <0x05d0 0x1b16999b>,
			    <0x05d4 0x1b16999b>,
			    <0x05d8 0x1b16999b>,
			    <0x05dc 0x1b16999b>,
			    <0x05e0 0x16856d4d>,
			    <0x05e4 0x111404f1>,
			    <0x05e8 0x19b63d82>,
			    <0x05ec 0x19b63d82>,
			    <0x05f0 0x19b63d82>,
			    <0x05f4 0x19b63d82>,
			    <0x05f8 0x19b63d82>,
			    <0x05fc 0x25f96653>,
			    <0x0600 0x16a56d4d>,
			    <0x0604 0x293a3687>,
			    <0x0608 0x293a3687>,
			    <0x060c 0x293a3687>,
			    <0x0610 0x293a3687>,
			    <0x0614 0x293a3687>,
			    <0x0618 0x3b7ecfaf>,
			    <0x061c 0x34dd2343>,
			    <0x0620 0x293a3687>,
			    <0x0624 0x293a3687>,
			    <0x0628 0x293a3687>,
			    <0x062c 0x293a3687>,
			    <0x0630 0x293a3687>,
			    <0x0634 0x14d4f930>,
			    <0x0638 0x293a3687>,
			    <0x063c 0x293a3687>,
			    <0x0640 0x293a3687>,
			    <0x0644 0x293a3687>,
			    <0x0648 0x293a3687>,
			    <0x064c 0x1825d568>,
			    <0x0650 0x13048511>,
			    <0x0654 0x293a3687>,
			    <0x0658 0x293a3687>,
			    <0x065c 0x293a3687>,
			    <0x0660 0x293a3687>,
			    <0x0664 0x293a3687>,
			    <0x0668 0x25f96652>,
			    <0x066c 0x1825d569>,
			    <0x0670 0x287a027a>,
			    <0x0674 0x287a027a>,
			    <0x0678 0x287a027a>,
			    <0x067c 0x287a027a>,
			    <0x0680 0x287a027a>,
			    <0x0684 0x13048511>,
			    <0x0688 0x14d4f930>,
			    <0x068c 0x293a3687>,
			    <0x0690 0x293a3687>,
			    <0x0694 0x293a3687>,
			    <0x0698 0x293a3687>,
			    <0x069c 0x293a3687>,
			    <0x06a0 0x13048511>,
			    <0x06a4 0x293a7687>,
			    <0x06a8 0x2a0a6a93>,
			    <0x06ac 0x2a0a6a93>,
			    <0x06b0 0x2a0a6a93>,
			    <0x06b4 0x2a0a6a93>,
			    <0x06b8 0x1825d568>,
			    <0x06bc 0x111404f1>,
			    <0x06c0 0x293a3687>,
			    <0x06c4 0x293a3687>,
			    <0x06c8 0x293a3687>,
			    <0x06cc 0x293a3687>,
			    <0x06d0 0x293a3687>,
			    <0x06d4 0x293a3687>,
			    <0x06d8 0x19b63d82>,
			    <0x06dc 0x293a3687>,
			    <0x06e0 0x293a3687>,
			    <0x06e4 0x293a3687>,
			    <0x06e8 0x293a3687>,
			    <0x06ec 0x293a3687>,
			    <0x06f0 0x2448f636>,
			    <0x06f4 0x16856d4d>,
			    <0x06f8 0x293a3687>,
			    <0x06fc 0x293a3687>,
			    <0x0700 0x00000000>,
			    <0x0704 0x00000000>,
			    <0x0708 0x00000000>,
			    <0x070c 0x00000000>,
			    <0x0710 0x00000000>,
			    <0x0714 0x00000000>,
			    <0x0718 0x00000000>,
			    <0x071c 0x00000000>,
			    <0x0720 0x00000000>,
			    <0x0724 0x00000000>,
			    <0x0728 0x00000000>,
			    <0x072c 0x00000000>,
			    <0x0730 0x00000000>,
			    <0x0734 0x00000000>,
			    <0x0738 0x00000000>,
			    <0x073c 0x00000000>,
			    <0x0740 0x00000000>,
			    <0x0744 0x00000000>,
			    <0x0748 0x00000000>,
			    <0x074c 0x00000000>,
			    <0x0750 0x00000000>,
			    <0x0754 0x00000000>,
			    <0x0758 0x00000000>,
			    <0x075c 0x00000000>,
			    <0x0760 0x00000000>,
			    <0x0764 0x00000000>,
			    <0x0768 0x00000000>,
			    <0x076c 0x00000000>,
			    <0x0770 0x00000000>,
			    <0x0774 0x00000000>,
			    <0x0778 0x00000000>,
			    <0x077c 0x00000000>,
			    <0x0780 0x00000000>,
			    <0x0784 0x00000000>,
			    <0x0788 0x00000000>,
			    <0x078c 0x00000000>,
			    <0x0790 0x00000000>,
			    <0x0794 0x00000000>,
			    <0x0798 0x00000000>,
			    <0x079c 0x00000000>,
			    <0x07a0 0x00000000>,
			    <0x07a4 0x00000000>,
			    <0x07a8 0x00000000>,
			    <0x07ac 0x00000000>,
			    <0x07b0 0x00000000>,
			    <0x07b4 0x00000000>,
			    <0x07b8 0x00000000>,
			    <0x07bc 0x00000000>,
			    <0x07c0 0x00000000>,
			    <0x07c4 0x00000000>,
			    <0x07c8 0x00000000>,
			    <0x07cc 0x00000000>,
			    <0x07d0 0x00000000>,
			    <0x07d4 0x00000000>,
			    <0x07d8 0x00000000>,
			    <0x07dc 0x00000000>,
			    <0x07e0 0x00000000>,
			    <0x07e4 0x00000000>,
			    <0x07e8 0x00000000>,
			    <0x07ec 0x00000000>,
			    <0x07f0 0x00000000>,
			    <0x07f4 0x00000000>,
			    <0x07f8 0x00000000>,
			    <0x07fc 0x00000000>,
			    <0x0800 0x08b12400>,
			    <0x0804 0x1113c4c6>,
			    <0x0808 0x16853530>,
			    <0x080c 0x1b166d82>,
			    <0x0810 0x1ed76dc7>,
			    <0x0814 0x21b835fe>,
			    <0x0818 0x2448da29>,
			    <0x081c 0x26d97e52>,
			    <0x0820 0x293a1e7a>,
			    <0x0824 0x2b9ab2a0>,
			    <0x0828 0x2ddb46c5>,
			    <0x082c 0x2ffbd2e8>,
			    <0x0830 0x31dc4f09>,
			    <0x0834 0x33acc326>,
			    <0x0838 0x356d3743>,
			    <0x083c 0x372da35f>,
			    <0x0840 0x38ce137b>,
			    <0x0844 0x3a6e7b95>,
			    <0x0848 0x3bfedfaf>,
			    <0x084c 0x3d8f43c8>,
			    <0x0850 0x3effa3e0>,
			    <0x0854 0x000ffff7>,
			    <0x0858 0x00000000>,
			    <0x085c 0x00000000>,
			    <0x0860 0x00000000>,
			    <0x0864 0x00000000>,
			    <0x0868 0x00000000>,
			    <0x086c 0x00000000>,
			    <0x0870 0x00000000>,
			    <0x0874 0x00000000>,
			    <0x0878 0x00000000>,
			    <0x087c 0x00000000>,
			    <0x0880 0x00000000>,
			    <0x0884 0x00000000>,
			    <0x0888 0x00000000>,
			    <0x088c 0x00000000>,
			    <0x0890 0x00000000>,
			    <0x0894 0x00000000>,
			    <0x0898 0x00000000>,
			    <0x089c 0x80000000>,
			    <0x08a0 0x00000000>,
			    <0x08a4 0x00000000>,
			    <0x08a8 0x00000000>,
			    <0x08ac 0x00000000>,
			    <0x08b0 0x00000000>;

			  ime_reg_cfg = 
			    <0x0004 0x0a003404>,
			    <0x0008 0x00000200>,
			    <0x000c 0x80000000>,
			    <0x0010 0x00000000>,
			    <0x0014 0x00000000>,
			    <0x0018 0xa0004000>,
			    <0x001c 0x40000300>,
			    <0x0020 0x04380780>,
			    <0x0024 0x00000020>,
			    <0x0028 0x001e0000>,
			    <0x002c 0x1f040438>,
			    <0x0030 0x00000140>,
			    <0x0034 0x00000140>,
			    <0x0038 0x003c0000>,
			    <0x003c 0x003d2c00>,
			    <0x0040 0x003e5800>,
			    <0x0044 0x00000000>,
			    <0x0048 0x00000000>,
			    <0x004c 0x00000000>,
			    <0x0050 0x00000000>,
			    <0x0054 0x00000000>,
			    <0x0058 0x00000001>,
			    <0x005c 0x00000000>,
			    <0x0060 0x00000012>,
			    <0x0064 0x00000000>,
			    <0x0068 0x00000000>,
			    <0x006c 0x00000000>,
			    <0x0070 0x00000000>,
			    <0x0074 0x00000000>,
			    <0x0078 0x00000000>,
			    <0x007c 0x04380780>,
			    <0x0080 0x00000000>,
			    <0x0084 0x04380780>,
			    <0x0088 0xff00ff00>,
			    <0x008c 0x00000780>,
			    <0x0090 0x00000780>,
			    <0x0094 0x0210f000>,
			    <0x0098 0x02309400>,
			    <0x009c 0x00000000>,
			    <0x00a0 0x00000000>,
			    <0x00a4 0x00000000>,
			    <0x00a8 0x00000000>,
			    <0x00ac 0x00000000>,
			    <0x00b0 0x00000012>,
			    <0x00b4 0x00000000>,
			    <0x00b8 0x00000000>,
			    <0x00bc 0x01000100>,
			    <0x00c0 0x10001000>,
			    <0x00c4 0x10001000>,
			    <0x00c8 0x10001000>,
			    <0x00cc 0x00000000>,
			    <0x00d0 0x00000000>,
			    <0x00d4 0x00000000>,
			    <0x00d8 0x00000000>,
			    <0x00dc 0x00000000>,
			    <0x00e0 0x00000000>,
			    <0x00e4 0x00000000>,
			    <0x00e8 0x00000000>,
			    <0x00ec 0x00000000>,
			    <0x00f0 0x00000000>,
			    <0x00f4 0x00000000>,
			    <0x00f8 0x00000000>,
			    <0x00fc 0x00000000>,
			    <0x0100 0x00000000>,
			    <0x0104 0x00f00140>,
			    <0x0108 0x00000000>,
			    <0x010c 0x00f00140>,
			    <0x0110 0xff00ff00>,
			    <0x0114 0x00000050>,
			    <0x0118 0x00000050>,
			    <0x011c 0x0043da00>,
			    <0x0120 0x00456780>,
			    <0x0124 0x00000000>,
			    <0x0128 0x00000000>,
			    <0x012c 0x00000000>,
			    <0x0130 0x00000012>,
			    <0x0134 0x00000000>,
			    <0x0138 0x00000000>,
			    <0x013c 0x01000100>,
			    <0x0140 0x10001000>,
			    <0x0144 0x10001000>,
			    <0x0148 0x10001000>,
			    <0x014c 0x00000000>,
			    <0x0150 0x00000000>,
			    <0x0154 0x00000000>,
			    <0x0158 0x00000000>,
			    <0x015c 0x00000000>,
			    <0x0160 0x00000000>,
			    <0x0164 0x00000000>,
			    <0x0168 0x00000000>,
			    <0x016c 0x00000000>,
			    <0x0170 0x00000000>,
			    <0x0174 0x00000000>,
			    <0x0178 0x00000000>,
			    <0x017c 0x00000000>,
			    <0x0180 0x00000000>,
			    <0x0184 0x00f00140>,
			    <0x0188 0x00000000>,
			    <0x018c 0x00f00140>,
			    <0x0190 0xff00ff00>,
			    <0x0194 0x00000140>,
			    <0x0198 0x00000140>,
			    <0x019c 0x0046b900>,
			    <0x01a0 0x00485d00>,
			    <0x01a4 0x00000000>,
			    <0x01a8 0x00000000>,
			    <0x01ac 0x00000000>,
			    <0x01b0 0x00000000>,
			    <0x01b4 0x00000000>,
			    <0x01b8 0x00000000>,
			    <0x01bc 0x00000000>,
			    <0x01c0 0x00000000>,
			    <0x01c4 0x00000000>,
			    <0x01c8 0x00000000>,
			    <0x01cc 0x00000000>,
			    <0x01d0 0x00000000>,
			    <0x01d4 0x00000000>,
			    <0x01d8 0x00000000>,
			    <0x01dc 0x00000000>,
			    <0x01e0 0x00000000>,
			    <0x01e4 0x00000000>,
			    <0x01e8 0x00000000>,
			    <0x01ec 0x00000000>,
			    <0x01f0 0x00000000>,
			    <0x01f4 0x00000000>,
			    <0x01f8 0x00000000>,
			    <0x01fc 0x00000000>,
			    <0x0200 0x00000000>,
			    <0x0204 0x00000000>,
			    <0x0208 0x00000000>,
			    <0x020c 0x00000000>,
			    <0x0210 0x00000000>,
			    <0x0214 0x00000000>,
			    <0x0218 0x00000000>,
			    <0x021c 0x00000000>,
			    <0x0220 0x011001e0>,
			    <0x0224 0x404b3fe6>,
			    <0x0228 0x000005a0>,
			    <0x022c 0x02bc6000>,
			    <0x0230 0x00000000>,
			    <0x0234 0x00000000>,
			    <0x0238 0x0002000a>,
			    <0x023c 0x000013ff>,
			    <0x0240 0x0002000a>,
			    <0x0244 0x00200022>,
			    <0x0248 0x0200000a>,
			    <0x024c 0x00000000>,
			    <0x0250 0x8000010c>,
			    <0x0254 0xfb46019a>,
			    <0x0258 0x03fc0402>,
			    <0x025c 0x040503ff>,
			    <0x0260 0x040403fe>,
			    <0x0264 0x040303fd>,
			    <0x0268 0x000005a0>,
			    <0x026c 0x02bc6000>,
			    <0x0270 0x00000505>,
			    <0x0274 0x00000000>,
			    <0x0278 0x00000000>,
			    <0x027c 0x00000000>,
			    <0x0280 0x00508080>,
			    <0x0284 0x16c6b9f0>,
			    <0x0288 0x0a63a12a>,
			    <0x028c 0x00008864>,
			    <0x0290 0x16c6b9f0>,
			    <0x0294 0x0a63a12a>,
			    <0x0298 0x00008864>,
			    <0x029c 0x00000000>,
			    <0x02a0 0x00000000>,
			    <0x02a4 0x00000000>,
			    <0x02a8 0x00000000>,
			    <0x02ac 0x00000000>,
			    <0x02b0 0x00000000>,
			    <0x02b4 0x00000000>,
			    <0x02b8 0x00000000>,
			    <0x02bc 0x00000000>,
			    <0x02c0 0x00000000>,
			    <0x02c4 0x00000000>,
			    <0x02c8 0x00000000>,
			    <0x02cc 0x00000000>,
			    <0x02d0 0x00000000>,
			    <0x02d4 0x00000000>,
			    <0x02d8 0x00000000>,
			    <0x02dc 0x00000000>,
			    <0x02e0 0x00000000>,
			    <0x02e4 0x00000000>,
			    <0x02e8 0x00000000>,
			    <0x02ec 0x00000000>,
			    <0x02f0 0x00000000>,
			    <0x02f4 0x00000000>,
			    <0x02f8 0x00000000>,
			    <0x02fc 0x00000000>,
			    <0x0300 0x00000000>,
			    <0x0304 0x00000000>,
			    <0x0308 0x00000000>,
			    <0x030c 0x00000000>,
			    <0x0310 0x00000000>,
			    <0x0314 0x00000000>,
			    <0x0318 0x00000000>,
			    <0x031c 0x00000000>,
			    <0x0320 0x00000000>,
			    <0x0324 0x00000000>,
			    <0x0328 0x00000000>,
			    <0x032c 0x00000000>,
			    <0x0330 0x00000000>,
			    <0x0334 0x00000000>,
			    <0x0338 0x00000000>,
			    <0x033c 0x00000000>,
			    <0x0340 0x00000000>,
			    <0x0344 0x00000000>,
			    <0x0348 0x00000000>,
			    <0x034c 0x00000000>,
			    <0x0350 0x00000000>,
			    <0x0354 0x00000000>,
			    <0x0358 0x00000000>,
			    <0x035c 0x00000000>,
			    <0x0360 0x00000000>,
			    <0x0364 0x00000000>,
			    <0x0368 0x00000000>,
			    <0x036c 0x00000000>,
			    <0x0370 0x00000000>,
			    <0x0374 0x00000000>,
			    <0x0378 0x00000000>,
			    <0x037c 0x00000000>,
			    <0x0380 0x00000000>,
			    <0x0384 0x00000000>,
			    <0x0388 0x00000000>,
			    <0x038c 0x00000000>,
			    <0x0390 0x00000000>,
			    <0x0394 0x00000000>,
			    <0x0398 0x00000000>,
			    <0x039c 0x00000000>,
			    <0x03a0 0x00000000>,
			    <0x03a4 0x00000000>,
			    <0x03a8 0x00000000>,
			    <0x03ac 0x00000000>,
			    <0x03b0 0x00000000>,
			    <0x03b4 0x00000000>,
			    <0x03b8 0x00000000>,
			    <0x03bc 0x00000000>,
			    <0x03c0 0x00000000>,
			    <0x03c4 0x00000000>,
			    <0x03c8 0x00000000>,
			    <0x03cc 0x00000000>,
			    <0x03d0 0x00000000>,
			    <0x03d4 0x00000000>,
			    <0x03d8 0x00000000>,
			    <0x03dc 0x00000000>,
			    <0x03e0 0x00000000>,
			    <0x03e4 0x00000000>,
			    <0x03e8 0x00000000>,
			    <0x03ec 0x00000000>,
			    <0x03f0 0x00000000>,
			    <0x03f4 0x00000000>,
			    <0x03f8 0x00000000>,
			    <0x03fc 0x00000000>,
			    <0x0400 0x00000000>,
			    <0x0404 0x00000000>,
			    <0x0408 0x00000000>,
			    <0x040c 0x00000000>,
			    <0x0410 0x00000000>,
			    <0x0414 0x00000000>,
			    <0x0418 0x00000000>,
			    <0x041c 0x00000000>,
			    <0x0420 0x00000000>,
			    <0x0424 0x00000000>,
			    <0x0428 0x00000000>,
			    <0x042c 0x00000000>,
			    <0x0430 0x00000000>,
			    <0x0434 0x00000000>,
			    <0x0438 0x00000000>,
			    <0x043c 0x00000000>,
			    <0x0440 0x00000000>,
			    <0x0444 0x00000000>,
			    <0x0448 0x00000000>,
			    <0x044c 0x00000000>,
			    <0x0450 0x00000000>,
			    <0x0454 0x00000000>,
			    <0x0458 0x00000000>,
			    <0x045c 0x00000000>,
			    <0x0460 0x00000000>,
			    <0x0464 0x00000000>,
			    <0x0468 0x00000000>,
			    <0x046c 0x00000000>,
			    <0x0470 0x00000000>,
			    <0x0474 0x00000000>,
			    <0x0478 0x00000000>,
			    <0x047c 0x00000000>,
			    <0x0480 0x00000000>,
			    <0x0484 0x00000000>,
			    <0x0488 0x00000000>,
			    <0x048c 0x00000000>,
			    <0x0490 0x00000000>,
			    <0x0494 0x00000000>,
			    <0x0498 0x00000000>,
			    <0x049c 0x00000000>,
			    <0x04a0 0x00000000>,
			    <0x04a4 0x00000000>,
			    <0x04a8 0x00000000>,
			    <0x04ac 0x00000000>,
			    <0x04b0 0x00000000>,
			    <0x04b4 0x00000000>,
			    <0x04b8 0x00000000>,
			    <0x04bc 0x00000000>,
			    <0x04c0 0x00000000>,
			    <0x04c4 0x00000000>,
			    <0x04c8 0x00000000>,
			    <0x04cc 0x00000000>,
			    <0x04d0 0x00000000>,
			    <0x04d4 0x00000000>,
			    <0x04d8 0x00000000>,
			    <0x04dc 0x00000000>,
			    <0x04e0 0x00000000>,
			    <0x04e4 0x00000000>,
			    <0x04e8 0x00000000>,
			    <0x04ec 0x00000000>,
			    <0x04f0 0x00000000>,
			    <0x04f4 0x00000000>,
			    <0x04f8 0x00000000>,
			    <0x04fc 0x00000000>,
			    <0x0500 0x00000000>,
			    <0x0504 0x00000000>,
			    <0x0508 0x00000000>,
			    <0x050c 0x00000000>,
			    <0x0510 0x00000000>,
			    <0x0514 0x00000000>,
			    <0x0518 0x00000000>,
			    <0x051c 0x00000000>,
			    <0x0520 0x00000000>,
			    <0x0524 0x00000000>,
			    <0x0528 0x00000000>,
			    <0x052c 0x00000000>,
			    <0x0530 0x00000000>,
			    <0x0534 0x00000000>,
			    <0x0538 0x00000000>,
			    <0x053c 0x00000000>,
			    <0x0540 0x00000000>,
			    <0x0544 0x00000000>,
			    <0x0548 0x00000000>,
			    <0x054c 0x00000000>,
			    <0x0550 0x00000000>,
			    <0x0554 0x00000000>,
			    <0x0558 0x00000000>,
			    <0x055c 0x00000000>,
			    <0x0560 0x00000000>,
			    <0x0564 0x00000000>,
			    <0x0568 0x00000000>,
			    <0x056c 0x00000000>,
			    <0x0570 0x01e20fff>,
			    <0x0574 0x00000000>,
			    <0x0578 0x00000000>,
			    <0x057c 0x00000000>,
			    <0x0580 0x00000000>,
			    <0x0584 0x00000000>,
			    <0x0588 0x00000000>,
			    <0x058c 0x00000000>,
			    <0x0590 0x00000000>,
			    <0x0594 0x00000000>,
			    <0x0598 0x00000000>,
			    <0x059c 0x00000000>,
			    <0x05a0 0x0126077f>,
			    <0x05a4 0x00000000>,
			    <0x05a8 0x00000000>,
			    <0x05ac 0x00000000>,
			    <0x05b0 0x00000000>,
			    <0x05b4 0x01250780>,
			    <0x05b8 0x00000000>,
			    <0x05bc 0x00000000>,
			    <0x05c0 0x00000000>,
			    <0x05c4 0x00000000>,
			    <0x05c8 0x00000000>,
			    <0x05cc 0x00000000>,
			    <0x05d0 0x00000000>,
			    <0x05d4 0x00000000>,
			    <0x05d8 0x00000000>,
			    <0x05dc 0x00000000>,
			    <0x05e0 0x00000000>,
			    <0x05e4 0x00000000>,
			    <0x05e8 0x00000000>,
			    <0x05ec 0x00000000>,
			    <0x05f0 0x00000000>,
			    <0x05f4 0x80000000>,
			    <0x05f8 0x00000000>,
			    <0x05fc 0x00000000>,
			    <0x0600 0x80308f62>,
			    <0x0604 0x00000000>,
			    <0x0608 0x00000000>,
			    <0x060c 0x00000000>,
			    <0x0610 0x00000000>,
			    <0x0614 0x00000000>,
			    <0x0618 0x00000000>,
			    <0x061c 0x0318e8dd>,
			    <0x0620 0x0000000b>,
			    <0x0624 0x00000000>,
			    <0x0628 0x00014050>,
			    <0x062c 0x0a0280a0>,
			    <0x0630 0x000398e6>,
			    <0x0634 0x06060606>,
			    <0x0638 0x08070706>,
			    <0x063c 0x00000f80>,
			    <0x0640 0x44444344>,
			    <0x0644 0x001033c7>,
			    <0x0648 0x00000000>,
			    <0x064c 0x00000000>,
			    <0x0650 0x00000000>,
			    <0x0654 0x00000014>,
			    <0x0658 0x00000000>,
			    <0x065c 0x00000000>,
			    <0x0660 0x0b0a0a0b>,
			    <0x0664 0x09090909>,
			    <0x0668 0x00460050>,
			    <0x066c 0x00460046>,
			    <0x0670 0x003c003c>,
			    <0x0674 0x003c003c>,
			    <0x0678 0x003c0032>,
			    <0x067c 0x00420040>,
			    <0x0680 0x00440044>,
			    <0x0684 0x00460046>,
			    <0x0688 0x00001008>,
			    <0x068c 0x00000000>,
			    <0x0690 0x00000000>,
			    <0x0694 0x00000000>,
			    <0x0698 0x00000000>,
			    <0x069c 0x00000000>,
			    <0x06a0 0x01900190>,
			    <0x06a4 0x01900190>,
			    <0x06a8 0x051401f4>,
			    <0x06ac 0x05140514>,
			    <0x06b0 0x0b0a0a0b>,
			    <0x06b4 0x09090909>,
			    <0x06b8 0x00460050>,
			    <0x06bc 0x00460046>,
			    <0x06c0 0x003c003c>,
			    <0x06c4 0x003c003c>,
			    <0x06c8 0x003c0032>,
			    <0x06cc 0x00420040>,
			    <0x06d0 0x00440044>,
			    <0x06d4 0x00460046>,
			    <0x06d8 0x00001008>,
			    <0x06dc 0x00000000>,
			    <0x06e0 0x00000000>,
			    <0x06e4 0x00000000>,
			    <0x06e8 0x00000000>,
			    <0x06ec 0x00000000>,
			    <0x06f0 0x00001008>,
			    <0x06f4 0x00000000>,
			    <0x06f8 0x00000000>,
			    <0x06fc 0x00000000>,
			    <0x0700 0x00000000>,
			    <0x0704 0x00000000>,
			    <0x0708 0x00000000>,
			    <0x070c 0x00000000>,
			    <0x0710 0x00001008>,
			    <0x0714 0x00000000>,
			    <0x0718 0x00000000>,
			    <0x071c 0x00000000>,
			    <0x0720 0x00000000>,
			    <0x0724 0x00000000>,
			    <0x0728 0x00000000>,
			    <0x072c 0x00000000>,
			    <0x0730 0x3fff0403>,
			    <0x0734 0x00002010>,
			    <0x0738 0x04000200>,
			    <0x073c 0x00200020>,
			    <0x0740 0x00000000>,
			    <0x0744 0x00000000>,
			    <0x0748 0x00000000>,
			    <0x074c 0x00000000>,
			    <0x0750 0x00000000>,
			    <0x0754 0x00000000>,
			    <0x0758 0x00000000>,
			    <0x075c 0x00000000>,
			    <0x0760 0x00ff0603>,
			    <0x0764 0x018000c0>,
			    <0x0768 0x00000000>,
			    <0x076c 0x01010101>,
			    <0x0770 0x20201010>,
			    <0x0774 0x00000000>,
			    <0x0778 0x00000000>,
			    <0x077c 0x00000000>,
			    <0x0780 0x00000000>,
			    <0x0784 0x00000000>,
			    <0x0788 0x00000000>,
			    <0x078c 0x00000000>,
			    <0x0790 0x10101010>,
			    <0x0794 0x10101010>,
			    <0x0798 0x00000000>,
			    <0x079c 0x00000000>,
			    <0x07a0 0x00000000>,
			    <0x07a4 0x00000000>,
			    <0x07a8 0x00000000>,
			    <0x07ac 0x00000000>,
			    <0x07b0 0x3c2c160b>,
			    <0x07b4 0x00000000>,
			    <0x07b8 0x00000000>,
			    <0x07bc 0x00000000>,
			    <0x07c0 0x37004080>,
			    <0x07c4 0x0033b34f>,
			    <0x07c8 0x03190319>,
			    <0x07cc 0x00004080>,
			    <0x07d0 0x1b130b00>,
			    <0x07d4 0x3a312b23>,
			    <0x07d8 0x1e150d00>,
			    <0x07dc 0x3c312923>,
			    <0x07e0 0x00004080>,
			    <0x07e4 0x00000000>,
			    <0x07e8 0x00000000>,
			    <0x07ec 0x00000000>,
			    <0x07f0 0x00000000>,
			    <0x07f4 0x00000000>,
			    <0x07f8 0x00000000>,
			    <0x07fc 0x00000000>,
			    <0x0800 0x00000780>,
			    <0x0804 0x00000780>,
			    <0x0808 0x026ff000>,
			    <0x080c 0x028f9400>,
			    <0x0810 0x00000000>,
			    <0x0814 0x00000000>,
			    <0x0818 0x00000000>,
			    <0x081c 0x00000000>,
			    <0x0820 0x00000010>,
			    <0x0824 0x02c45280>,
			    <0x0828 0x00000000>,
			    <0x082c 0x02c45280>,
			    <0x0830 0x00000010>,
			    <0x0834 0x02c456c0>,
			    <0x0838 0x000001e0>,
			    <0x083c 0x02c25a00>,
			    <0x0840 0x00000000>,
			    <0x0844 0x02c25a00>,
			    <0x0848 0x00000000>,
			    <0x084c 0x00000000>,
			    <0x0850 0x00000000>,
			    <0x0854 0x00000000>,
			    <0x0858 0x00000000>,
			    <0x085c 0x00000000>,
			    <0x0860 0x00000000>,
			    <0x0864 0x00000000>,
			    <0x0868 0x00000000>,
			    <0x086c 0x00000000>,
			    <0x0870 0x00000000>,
			    <0x0874 0x00000000>,
			    <0x0878 0x00000000>,
			    <0x087c 0x00000000>,
			    <0x0880 0x00000000>,
			    <0x0884 0x00000000>,
			    <0x0888 0x00000000>,
			    <0x088c 0x00000000>,
			    <0x0890 0x00000000>,
			    <0x0894 0x00000000>,
			    <0x0898 0x00000000>,
			    <0x089c 0x00000000>,
			    <0x08a0 0x00000000>,
			    <0x08a4 0x00000000>,
			    <0x08a8 0x00000000>,
			    <0x08ac 0x00000000>,
			    <0x08b0 0x00000000>,
			    <0x08b4 0x00000000>,
			    <0x08b8 0x00000000>,
			    <0x08bc 0x00000000>,
			    <0x08c0 0x00000000>,
			    <0x08c4 0x00000000>,
			    <0x08c8 0x00000000>,
			    <0x08cc 0x00000000>,
			    <0x08d0 0x00000000>,
			    <0x08d4 0x00000000>,
			    <0x08d8 0x00000000>,
			    <0x08dc 0x00000000>,
			    <0x08e0 0x00000000>,
			    <0x08e4 0x00000000>,
			    <0x08e8 0x00000000>,
			    <0x08ec 0x00000000>,
			    <0x08f0 0x00000000>,
			    <0x08f4 0x00000000>,
			    <0x08f8 0x00000000>,
			    <0x08fc 0x00000000>,
			    <0x0900 0x00000000>,
			    <0x0904 0x00000000>,
			    <0x0908 0x00000000>,
			    <0x090c 0x00000000>,
			    <0x0910 0x0bb41249>,
			    <0x0914 0x00000748>,
			    <0x0918 0x08e80e39>,
			    <0x091c 0x000005a6>,
			    <0x0920 0x08080ccd>,
			    <0x0924 0x0000051f>,
			    <0x0928 0x07500ba3>,
			    <0x092c 0x000004ae>,
			    <0x0930 0x063509d9>,
			    <0x0934 0x000003f3>,
			    <0x0938 0x05c50925>,
			    <0x093c 0x000003a4>,
			    <0x0940 0x050f0800>,
			    <0x0944 0x00000336>,
			    <0x0948 0x0480071c>,
			    <0x094c 0x000002d9>,
			    <0x0950 0x040e0666>,
			    <0x0954 0x0000028f>,
			    <0x0958 0x03b105d1>,
			    <0x095c 0x00000253>,
			    <0x0960 0x031a04ec>,
			    <0x0964 0x000001f9>,
			    <0x0968 0x02e20492>,
			    <0x096c 0x000001d5>,
			    <0x0970 0x02870400>,
			    <0x0974 0x00000199>,
			    <0x0978 0x0240038e>,
			    <0x097c 0x0000016d>,
			    <0x0980 0x02070333>,
			    <0x0984 0x00000148>,
			    <0x0988 0x01730249>,
			    <0x098c 0x000000ea>,
			    <0x0990 0x00e30124>,
			    <0x0994 0x00ba00cc>,
			    <0x0998 0x0092009d>,
			    <0x099c 0x00720080>,
			    <0x09a0 0x005d0066>,
			    <0x09a4 0x0049004f>,
			    <0x09a8 0x00390040>,
			    <0x09ac 0x00250033>,
			    <0x09b0 0x00000000>,
			    <0x09b4 0x00000000>,
			    <0x09b8 0x00000000>,
			    <0x09bc 0x00000000>,
			    <0x09c0 0x0023001c>,
			    <0x09c4 0x0000002d>,
			    <0x09c8 0x002e0024>,
			    <0x09cc 0x0000003a>,
			    <0x09d0 0x00330028>,
			    <0x09d4 0x00000040>,
			    <0x09d8 0x0038002c>,
			    <0x09dc 0x00000046>,
			    <0x09e0 0x00420034>,
			    <0x09e4 0x00000053>,
			    <0x09e8 0x00470038>,
			    <0x09ec 0x0000005a>,
			    <0x09f0 0x00510040>,
			    <0x09f4 0x00000066>,
			    <0x09f8 0x005b0048>,
			    <0x09fc 0x00000073>,
			    <0x0a00 0x00650050>,
			    <0x0a04 0x00000080>,
			    <0x0a08 0x006f0058>,
			    <0x0a0c 0x0000008d>,
			    <0x0a10 0x00840068>,
			    <0x0a14 0x000000a6>,
			    <0x0a18 0x008e0070>,
			    <0x0a1c 0x000000b3>,
			    <0x0a20 0x00a20080>,
			    <0x0a24 0x000000cd>,
			    <0x0a28 0x00b60090>,
			    <0x0a2c 0x000000e6>,
			    <0x0a30 0x00ca00a0>,
			    <0x0a34 0x00000100>,
			    <0x0a38 0x011b00e0>,
			    <0x0a3c 0x00000166>,
			    <0x0a40 0x6955422e>,
			    <0x0a44 0xb7a4907d>,
			    <0x0a48 0x00000000>,
			    <0x0a4c 0x00000000>,
			    <0x0a50 0x00000000>,
			    <0x0a54 0x00000000>,
			    <0x0a58 0x00000000>,
			    <0x0a5c 0x00000000>,
			    <0x0a60 0x00000001>,
			    <0x0a64 0x00000000>,
			    <0x0a68 0x00000000>,
			    <0x0a6c 0x00000000>,
			    <0x0a70 0x00000000>,
			    <0x0a74 0x00000000>,
			    <0x0a78 0x00000000>,
			    <0x0a7c 0x00000000>,
			    <0x0a80 0x00000000>,
			    <0x0a84 0x00000000>,
			    <0x0a88 0x00000000>,
			    <0x0a8c 0x00000000>,
			    <0x0a90 0x00000000>,
			    <0x0a94 0x00000000>,
			    <0x0a98 0x00000000>,
			    <0x0a9c 0x00000000>,
			    <0x0aa0 0x00000000>,
			    <0x0aa4 0x00000000>,
			    <0x0aa8 0x00000000>,
			    <0x0aac 0x00000000>,
			    <0x0ab0 0x00000000>,
			    <0x0ab4 0x00000000>,
			    <0x0ab8 0x00000000>,
			    <0x0abc 0x00000000>;

			};
		};
	};
};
